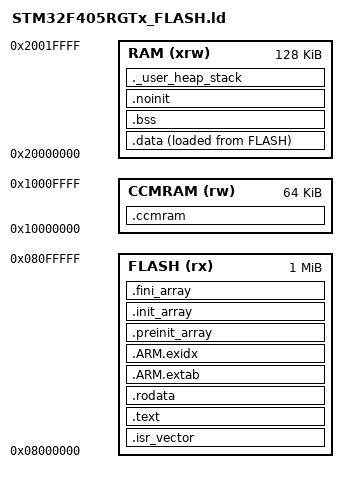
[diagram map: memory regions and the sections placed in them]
/* STM32F405RGTx : 1 Mo de flash, 128 Ko de SRAM, 64 Ko de CCM (pas accessible par le DMA). */

ENTRY(Reset_Handler)

_Min_Heap_Size  = 0x0;   /* pas de malloc : FreeRTOS gère sa mémoire (allocation statique) */
_Min_Stack_Size = 0x800; /* pile de main() et des interruptions */

MEMORY
{
    FLASH  (rx)  : ORIGIN = 0x08000000, LENGTH = 1024K
    RAM    (xrw) : ORIGIN = 0x20000000, LENGTH = 128K
    CCMRAM (rw)  : ORIGIN = 0x10000000, LENGTH = 64K
}

_estack = ORIGIN(RAM) + LENGTH(RAM);
SECTIONS
{
    .isr_vector :
    {
        . = ALIGN(4);
        KEEP(*(.isr_vector))
        . = ALIGN(4);
    } > FLASH

    .text :
    {
        . = ALIGN(4);
        *(.text*)
        *(.glue_7) *(.glue_7t) *(.eh_frame)
        KEEP(*(.init))
        KEEP(*(.fini))
        . = ALIGN(4);
        _etext = .;
    } > FLASH

    .rodata :
    {
        . = ALIGN(4);
        *(.rodata*)
        . = ALIGN(4);
    } > FLASH

    .ARM.extab : { *(.ARM.extab* .gnu.linkonce.armextab.*) } > FLASH
    .ARM.exidx :
    {
        __exidx_start = .;
        *(.ARM.exidx*)
        __exidx_end = .;
    } > FLASH

    .preinit_array :
    {
        PROVIDE_HIDDEN(__preinit_array_start = .);
        KEEP(*(.preinit_array*))
        PROVIDE_HIDDEN(__preinit_array_end = .);
    } > FLASH
    .init_array :
    {
        PROVIDE_HIDDEN(__init_array_start = .);
        KEEP(*(SORT(.init_array.*)))
        KEEP(*(.init_array*))
        PROVIDE_HIDDEN(__init_array_end = .);
    } > FLASH
    .fini_array :
    {
        PROVIDE_HIDDEN(__fini_array_start = .);
        KEEP(*(SORT(.fini_array.*)))
        KEEP(*(.fini_array*))
        PROVIDE_HIDDEN(__fini_array_end = .);
    } > FLASH

    _sidata = LOADADDR(.data);

    .data :
    {
        . = ALIGN(4);
        _sdata = .;
        *(.data*)
        . = ALIGN(4);
        _edata = .;
    } > RAM AT > FLASH

    .bss (NOLOAD) :
    {
        . = ALIGN(4);
        _sbss = .;
        __bss_start__ = _sbss;
        *(.bss*)
        *(COMMON)
        . = ALIGN(4);
        _ebss = .;
        __bss_end__ = _ebss;
    } > RAM

    /* Ni initialisé ni remis à zéro au démarrage : survit à un reset logiciel. */
    .noinit (NOLOAD) :
    {
        . = ALIGN(4);
        *(.noinit*)
        . = ALIGN(4);
    } > RAM

    /* Données rapides non initialisées (pas accessibles par le DMA). */
    .ccmram (NOLOAD) :
    {
        . = ALIGN(4);
        *(.ccmram*)
        . = ALIGN(4);
    } > CCMRAM

    /* Vérifie à l'édition de liens qu'il reste la place pour la pile. */
    ._user_heap_stack (NOLOAD) :
    {
        . = ALIGN(8);
        PROVIDE(end = .);
        PROVIDE(_end = .);
        . = . + _Min_Heap_Size;
        . = . + _Min_Stack_Size;
        . = ALIGN(8);
    } > RAM

    .ARM.attributes 0 : { *(.ARM.attributes) }
}
